AUTOSAR XML (schema 00049)
package /DataType/Implementation/CPP
  37 x std cpp implementation data type:
    bool: category=VALUE, type-emitter=FundamentalType
    float: category=VALUE, type-emitter=FundamentalType
    double: category=VALUE, type-emitter=FundamentalType
    uint8_t: category=VALUE, header-file=cstdint
    uint16_t: category=VALUE, header-file=cstdint
    uint32_t: category=VALUE, header-file=cstdint
    uint64_t: category=VALUE, header-file=cstdint
    int8_t: category=VALUE, header-file=cstdint
    int16_t: category=VALUE, header-file=cstdint
    int32_t: category=VALUE, header-file=cstdint
    int64_t: category=VALUE, header-file=cstdint
    String: category=STRING, header-file=ara/core/string.h
      namespaces:
        symbol props ara
        symbol props core
    DriveMode: compu {0=ECO, 1=COMFORT, 2=SPORT, 3=EMERGENCY}, header-file=vehicle_data/types.hpp, type-reference=uint8_t
      namespaces:
        symbol props vehicle_data
    SystemStatus: compu {0=OK, 1=WARNING, 2=ERROR, 3=CRITICAL}, header-file=vehicle_data/types.hpp, type-reference=uint8_t
      namespaces:
        symbol props vehicle_data
    GearPosition: compu {0=PARK, 1=REVERSE, 2=NEUTRAL, 3=DRIVE}, header-file=vehicle_data/types.hpp, type-reference=uint8_t
      namespaces:
        symbol props vehicle_data
    SpeedData: category=STRUCTURE, header-file=vehicle_data/types.hpp
      namespaces:
        symbol props vehicle_data
      cpp implementation data type element speed_kmh: type-reference=float
      cpp implementation data type element timestamp_us: type-reference=uint64_t
    CabinSensorData: category=STRUCTURE, header-file=vehicle_data/types.hpp
      namespaces:
        symbol props vehicle_data
      cpp implementation data type element temperature_c: type-reference=float
      cpp implementation data type element humidity_pct: type-reference=float
      cpp implementation data type element passenger_detected: type-reference=bool
    EmergencyAlert: category=STRUCTURE, header-file=vehicle_data/types.hpp
      namespaces:
        symbol props vehicle_data
      cpp implementation data type element alert_id: type-reference=uint32_t
      cpp implementation data type element reason: type-reference=String
    AlertPayload: category=STRUCTURE, header-file=vehicle_data/types.hpp
      namespaces:
        symbol props vehicle_data
      cpp implementation data type element code: type-reference=uint32_t
      cpp implementation data type element message: type-reference=String
    LocationPoint: category=STRUCTURE, header-file=vehicle_data/types.hpp
      namespaces:
        symbol props vehicle_data
      4 x cpp implementation data type element, all with category=TYPE_REFERENCE, type-reference=float:
        latitude
        longitude
        altitude
        speed_limit_kmh
    BatteryCell: category=STRUCTURE, header-file=vehicle_data/types.hpp
      namespaces:
        symbol props vehicle_data
      cpp implementation data type element cell_id: type-reference=uint32_t
      cpp implementation data type element voltage: type-reference=float
      cpp implementation data type element temperature: type-reference=float
    Vector3D: category=STRUCTURE, header-file=vehicle_data/types.hpp
      namespaces:
        symbol props vehicle_data
      cpp implementation data type element x: type-reference=double
      cpp implementation data type element y: type-reference=double
      cpp implementation data type element z: type-reference=double
    DiagnosticItem: category=STRUCTURE, header-file=vehicle_data/types.hpp
      namespaces:
        symbol props vehicle_data
      cpp implementation data type element code: type-reference=uint32_t
      cpp implementation data type element error_offset: type-reference=int32_t
      cpp implementation data type element message: type-reference=String
    WheelSpeeds: category=ARRAY, array-size=4, header-file=vehicle_data/types.hpp, cpp-template-argument=float
      namespaces:
        symbol props vehicle_data
    BatteryModule: category=ARRAY, array-size=4, header-file=vehicle_data/types.hpp, cpp-template-argument=BatteryCell
      namespaces:
        symbol props vehicle_data
    SystemStatusMatrix: category=ARRAY, array-size=4, header-file=vehicle_data/types.hpp, cpp-template-argument=SystemStatus
      namespaces:
        symbol props vehicle_data
    AlertList: category=VECTOR, header-file=vehicle_data/types.hpp, cpp-template-argument=EmergencyAlert
      namespaces:
        symbol props vehicle_data
    WaypointList: category=VECTOR, header-file=vehicle_data/types.hpp, cpp-template-argument=LocationPoint
      namespaces:
        symbol props vehicle_data
    HistoryBuffer: category=VECTOR, header-file=vehicle_data/types.hpp, cpp-template-argument=float
      namespaces:
        symbol props vehicle_data
    StringList: category=VECTOR, header-file=vehicle_data/types.hpp, cpp-template-argument=String
      namespaces:
        symbol props vehicle_data
    DriveModeHistory: category=VECTOR, header-file=vehicle_data/types.hpp, cpp-template-argument=DriveMode
      namespaces:
        symbol props vehicle_data
    ConfigMap: category=ASSOCIATIVE_MAP, header-file=vehicle_data/types.hpp, template-arguments=[String, String]
      namespaces:
        symbol props vehicle_data
    DiagnosticMap: category=ASSOCIATIVE_MAP, header-file=vehicle_data/types.hpp, template-arguments=[uint32_t, EmergencyAlert]
      namespaces:
        symbol props vehicle_data
    FeatureFlagMap: category=ASSOCIATIVE_MAP, header-file=vehicle_data/types.hpp, template-arguments=[String, bool]
      namespaces:
        symbol props vehicle_data
    OptionalSpeed: category=OPTIONAL, header-file=vehicle_data/types.hpp, cpp-template-argument=SpeedData
      namespaces:
        symbol props vehicle_data
    SensorPayload: category=UNION, header-file=vehicle_data/types.hpp
      namespaces:
        symbol props vehicle_data
      cpp implementation data type element speed: type-reference=SpeedData
      cpp implementation data type element cabin: type-reference=CabinSensorData
    VehicleDiagnostics: category=STRUCTURE, header-file=vehicle_data/types.hpp
      namespaces:
        symbol props vehicle_data
      12 x cpp implementation data type element, all with category=TYPE_REFERENCE:
        report_id: type-reference=uint32_t
        system_status: type-reference=SystemStatus
        current_gear: type-reference=GearPosition
        wheel_speeds: type-reference=WheelSpeeds
        active_alerts: type-reference=AlertList
        config_kv: type-reference=ConfigMap
        status_matrix: type-reference=SystemStatusMatrix
        feature_flags: type-reference=FeatureFlagMap
        tags: type-reference=StringList
        battery_module: type-reference=BatteryModule
        optional_speed: type-reference=OptionalSpeed
        sensor_payload: type-reference=SensorPayload
package /PortInterface/Service
  11 x service interface:
    PowertrainInterface
      namespaces:
        symbol props powertrain
      events:
        5 x data:
          VehicleSpeed: type=SpeedData
          CabinSensors: type=CabinSensorData
          WheelSpeeds: type=WheelSpeeds
          BatteryModuleStatus: type=BatteryModule
          SpeedHistory: type=HistoryBuffer
    BodyControlInterface
      namespaces:
        symbol props body_control
      4 x field, all with has-notifier=true:
        TargetCabinTemperature: type=float, has-getter=true, has-setter=true
        RainSensorLevel: type=uint32_t, has-getter=false, has-setter=false
        OutsideAirQuality: type=uint32_t, has-getter=true, has-setter=false
        WindowPosition: type=uint32_t, has-getter=false, has-setter=true
      methods:
        operation LockDoors
          arg lock: type=bool, direction=IN
          arg Result: type=bool, direction=OUT
        operation FlashLights: fire-and-forget=true
          arg duration_ms: type=uint32_t, direction=IN
          arg count: type=uint32_t, direction=IN
    NavigationInterface
      namespaces:
        symbol props infotainment
        symbol props geo
        symbol props navigation
      events:
        data CurrentLocation: type=LocationPoint
        data ActiveRoute: type=WaypointList
      methods:
        operation SetDestination
          4 x arg:
            latitude: type=float, direction=IN
            longitude: type=float, direction=IN
            priority: type=uint32_t, direction=IN
            Result: type=bool, direction=OUT
    VehicleSupervisorInterface
      namespaces:
        symbol props vehicle_supervisor
      events:
        6 x data:
          EmergencyAlert: type=EmergencyAlert
          DiagnosticsReport: type=VehicleDiagnostics
          ActiveDiagnosticMap: type=DiagnosticMap
          DriveHistory: type=DriveModeHistory
          PrimaryWarning: type=uint16_t
          SecondaryWarning: type=uint16_t
      7 x field:
        CurrentDriveMode: type=DriveMode, has-getter=true, has-notifier=false, has-setter=true
        ActiveAlerts: type=AlertList, has-getter=true, has-notifier=true, has-setter=true
        VehicleConfig: type=ConfigMap, has-getter=true, has-notifier=false, has-setter=true
        SystemMatrix: type=SystemStatusMatrix, has-getter=true, has-notifier=true, has-setter=false
        FeatureFlags: type=FeatureFlagMap, has-getter=true, has-notifier=false, has-setter=true
        HardwareRevision: type=uint32_t, has-getter=true, has-notifier=false, has-setter=false
        CalibrationKey: type=uint32_t, has-getter=false, has-notifier=false, has-setter=true
      methods:
        4 x operation:
          TriggerDiagnostic
            arg code: type=uint32_t, direction=IN
            arg Result: type=bool, direction=OUT
          CalibrateOdometer
            arg current_km: type=uint32_t, direction=IN
            arg Result: type=uint32_t, direction=OUT
          ResetTripMeter: fire-and-forget=true
          SetSpeedLimiter
            arg max_kmh: type=float, direction=IN
            arg active: type=bool, direction=IN
            arg Result: type=bool, direction=OUT
    HmiServiceInterface
      namespaces:
        symbol props hmi
      events:
        data StatusNotification: type=String
      methods:
        operation ShowPopup
          arg message: type=String, direction=IN
          arg priority: type=uint32_t, direction=IN
          arg Result: type=bool, direction=OUT
    FanOutBodyControlInterface
      namespaces:
        symbol props fan_out_body
      field OutsideAirQuality: type=uint32_t, has-getter=true, has-notifier=true, has-setter=false
      field WindowPosition: type=uint32_t, has-getter=false, has-notifier=true, has-setter=true
      methods:
        operation ResetTripMeter: fire-and-forget=true
    FanOutSupervisorInterface
      namespaces:
        symbol props fan_out_supervisor
      field CurrentDriveMode: type=DriveMode, has-getter=true, has-notifier=false, has-setter=true
      methods:
        operation TriggerDiagnostic: fire-and-forget=true
          arg code: type=uint32_t, direction=IN
        operation CalibrateOdometer
          arg current_km: type=uint32_t, direction=IN
          arg Result: type=uint32_t, direction=OUT
        operation PerformSelfTest
    FanOutSupervisorBroadcastInterface
      namespaces:
        symbol props fan_out_sup_broadcast
      events:
        data WarningNotice: type=AlertPayload
        data AuditTrail: type=AlertPayload
    FanOutAlertBroadcastInterface
      namespaces:
        symbol props fan_out_alert
      events:
        data EmergencyAlert: type=EmergencyAlert
    FanOutAlert3Interface
      namespaces:
        symbol props fan_out_alert3
      events:
        data EmergencyAlertCustom: type=EmergencyAlert
    FanOutSensorFlushInterface
      namespaces:
        symbol props fan_out_sensor
      methods:
        operation UniqueSensorFlush: fire-and-forget=true
package /PortInterface/PlatformInterfaces
  persistency file storage interface LogFileStorage
  persistency key value storage interface VehicleSettingsStorage
  phm health channel interface SystemHealthChannel
  phm supervised entity interface WatchdogSupervisedEntity
package /SwComponent/AdaptiveApplication
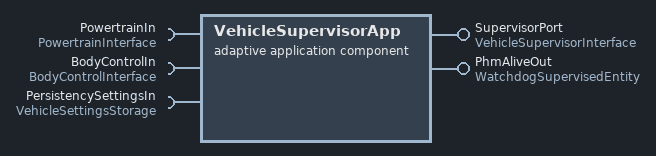
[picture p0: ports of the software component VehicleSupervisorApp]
  adaptive application sw component type VehicleSupervisorApp
    provide port SupervisorPort: provided-interface=VehicleSupervisorInterface
    provide port PhmAliveOut: provided-interface=WatchdogSupervisedEntity
    require port PowertrainIn: required-interface=PowertrainInterface
    require port BodyControlIn: required-interface=BodyControlInterface
    require port PersistencySettingsIn: required-interface=VehicleSettingsStorage
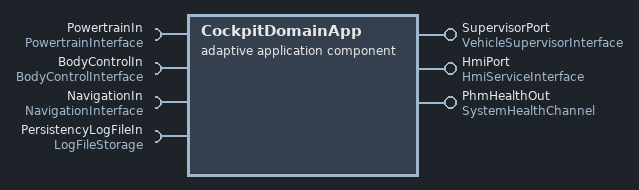
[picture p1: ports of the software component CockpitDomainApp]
  adaptive application sw component type CockpitDomainApp
    provide port SupervisorPort: provided-interface=VehicleSupervisorInterface
    provide port HmiPort: provided-interface=HmiServiceInterface
    provide port PhmHealthOut: provided-interface=SystemHealthChannel
    4 x require port:
      PowertrainIn: required-interface=PowertrainInterface
      BodyControlIn: required-interface=BodyControlInterface
      NavigationIn: required-interface=NavigationInterface
      PersistencyLogFileIn: required-interface=LogFileStorage
  adaptive application sw component type TelemetryApp
    provide port SupervisorPort: provided-interface=VehicleSupervisorInterface
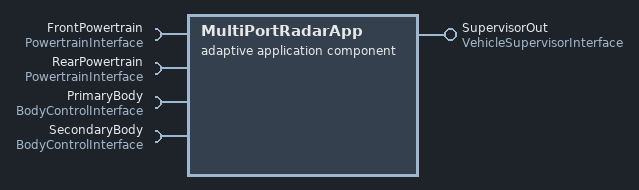
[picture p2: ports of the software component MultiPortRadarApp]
  adaptive application sw component type MultiPortRadarApp
    provide port SupervisorOut: provided-interface=VehicleSupervisorInterface
    4 x require port:
      FrontPowertrain: required-interface=PowertrainInterface
      RearPowertrain: required-interface=PowertrainInterface
      PrimaryBody: required-interface=BodyControlInterface
      SecondaryBody: required-interface=BodyControlInterface
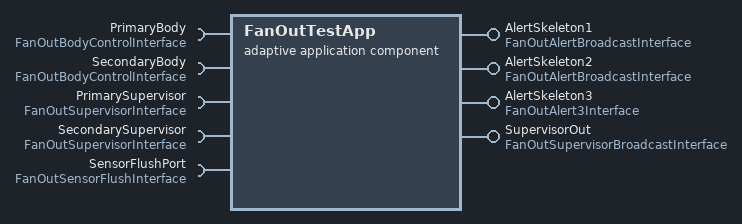
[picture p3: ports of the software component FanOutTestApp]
  adaptive application sw component type FanOutTestApp
    4 x provide port:
      AlertSkeleton1: provided-interface=FanOutAlertBroadcastInterface
      AlertSkeleton2: provided-interface=FanOutAlertBroadcastInterface
      AlertSkeleton3: provided-interface=FanOutAlert3Interface
      SupervisorOut: provided-interface=FanOutSupervisorBroadcastInterface
    5 x require port:
      PrimaryBody: required-interface=FanOutBodyControlInterface
      SecondaryBody: required-interface=FanOutBodyControlInterface
      PrimarySupervisor: required-interface=FanOutSupervisorInterface
      SecondarySupervisor: required-interface=FanOutSupervisorInterface
      SensorFlushPort: required-interface=FanOutSensorFlushInterface
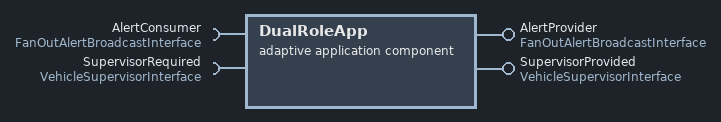
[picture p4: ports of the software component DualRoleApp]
  adaptive application sw component type DualRoleApp
    provide port AlertProvider: provided-interface=FanOutAlertBroadcastInterface
    provide port SupervisorProvided: provided-interface=VehicleSupervisorInterface
    require port AlertConsumer: required-interface=FanOutAlertBroadcastInterface
    require port SupervisorRequired: required-interface=VehicleSupervisorInterface
package /Deployment
  6 x executable:
    VehicleSupervisor
      root sw component prototype RootSwComponent: application-type=VehicleSupervisorApp
    CockpitDomain
      root sw component prototype RootSwComponent: application-type=CockpitDomainApp
    Telemetry
      root sw component prototype RootSwComponent: application-type=TelemetryApp
    MultiPortRadar
      root sw component prototype RootSwComponent: application-type=MultiPortRadarApp
    FanOutTest
      root sw component prototype RootSwComponent: application-type=FanOutTestApp
    DualRole
      root sw component prototype RootSwComponent: application-type=DualRoleApp
